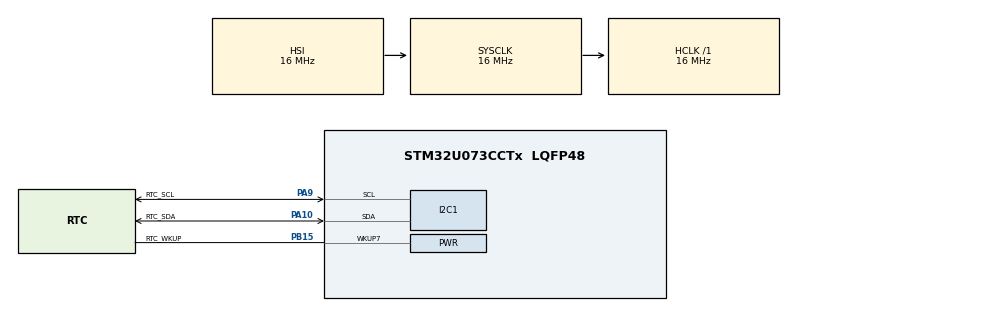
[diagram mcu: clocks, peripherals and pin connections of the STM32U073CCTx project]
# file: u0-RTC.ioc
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I2C1.Timing=0x00303D5B
Mcu.Family=STM32U0
Mcu.Name=STM32U073CCTx
Mcu.Package=LQFP48
NVIC.PriorityGroup=NVIC_PRIORITYGROUP_2
PA10.GPIO_Label=RTC_SDA
PA10.Mode=I2C
PA10.Signal=I2C1_SDA
PA13\ (SWDIO).GPIO_Label=SWDIO
PA13\ (SWDIO).Mode=Serial_Wire
PA13\ (SWDIO).Signal=DEBUG_JTMS-SWDIO
PA14\ (SWCLK).GPIO_Label=SWCLK
PA14\ (SWCLK).Mode=Serial_Wire
PA14\ (SWCLK).Signal=DEBUG_JTCK-SWCLK
PA9.GPIO_Label=RTC_SCL
PA9.Mode=I2C
PA9.Signal=I2C1_SCL
PB15.GPIO_Label=RTC_WKUP
PB15.Mode=WakeUp7
PB15.Signal=PWR_WKUP7
ProjectManager.HeapSize=0x200
ProjectManager.StackSize=0x400
ProjectManager.TargetToolchain=STM32CubeIDE
RCC.AHBFreq_Value=16000000
RCC.CortexFreq_Value=16000000
RCC.HCLKFreq_Value=16000000
RCC.HSE_VALUE=4000000
RCC.HSI48_VALUE=48000000
RCC.HSI_VALUE=16000000
RCC.LSE_VALUE=32768
RCC.MSI_VALUE=4000000
RCC.SYSCLKFreq_VALUE=16000000
RCC.VCOOutputFreq_Value=64000000
VP_PWR_VS_SECSignals.Mode=Security/Privilege
VP_RTC_VS_RTC_Activate.Mode=RTC_Enabled
board=custom

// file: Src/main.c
/* USER CODE BEGIN Header */
/**
  ******************************************************************************
  * @file           : main.c
  * @brief          : Main program body
  ******************************************************************************
  * @attention
  *
  * Copyright (c) 2026 STMicroelectronics.
  * All rights reserved.
  *
  * This software is licensed under terms that can be found in the LICENSE file
  * in the root directory of this software component.
  * If no LICENSE file comes with this software, it is provided AS-IS.
  *
  ******************************************************************************
  */
/* USER CODE END Header */
#include "main.h"

/* USER CODE BEGIN Includes */
#include "RV3028.h"
/* USER CODE END Includes */

I2C_HandleTypeDef hi2c1;

RTC_HandleTypeDef hrtc;

void SystemClock_Config(void);
static void MX_GPIO_Init(void);
static void MX_I2C1_Init(void);
static void MX_RTC_Init(void);

int main(void)
{

  /* MCU Configuration--------------------------------------------------------*/

  /* Reset of all peripherals, Initializes the Flash interface and the Systick. */
  HAL_Init();

  /* Configure the system clock */
  SystemClock_Config();

  /* Initialize all configured peripherals */
  MX_GPIO_Init();
  MX_I2C1_Init();
  MX_RTC_Init();
  /* USER CODE BEGIN 2 */
  //be able to debug in shutdown mode
  HAL_DBGMCU_EnableDBGStandbyMode();

  //wait until EEbusy low (not busy)
  uint8_t buffer[1];
  do{
	  RTC_read_register_value(&hi2c1, 0x0E, buffer, 1);
	  HAL_Delay(10);
  } while(buffer[0] & 0b10000000);

  HAL_StatusTypeDef status;

  if(__HAL_RCC_GET_FLAG(RCC_FLAG_PWRRST) == SET){
	  HAL_Delay(10000);
	  do{ status = RTC_init(&hi2c1); HAL_Delay(10); } while(status != HAL_OK);
	  __HAL_RCC_CLEAR_RESET_FLAGS(); //clear so it doesn't trigger on next cycle
  }

  //set time to 10 seconds before interrupt
  uint8_t time[] = {0x50,0x00,0x00,0x00,0b00000001,0b00000001,0x00};
  do{ status = RTC_set_register_value(&hi2c1, 0x00, time, 7); HAL_Delay(10); } while(status != HAL_OK);

  RTC_handle_interrupt(&hi2c1);

  HAL_Delay(3000); //DO NOT REMOVE, delay so debugger has time to connect and flash

  //increment day count (and store it) if woken from RTC/wakeup pin 7
  if(__HAL_PWR_GET_FLAG(PWR_FLAG_WUF7) == SET){
	  HAL_PWR_EnableBkUpAccess();
	  uint32_t dayCount = HAL_RTCEx_BKUPRead(&hrtc, RTC_BKP_DR0); //init value = 0
	  dayCount++;
	  HAL_RTCEx_BKUPWrite(&hrtc, RTC_BKP_DR0, dayCount);
	  HAL_PWR_DisableBkUpAccess();
  }

  //clears the wakeup flags from all pins by writing to power reset register which will clear power status register
  __HAL_PWR_CLEAR_FLAG(PWR_FLAG_WU);

  //Sets SLEEPDEEP bit, LPMS = 1xx in PWR_CR1 register, wakeup on interrupt (WFI)
  HAL_PWR_EnterSHUTDOWNMode();

  /* USER CODE END 2 */

  /* Infinite loop */
  while (1){

  }
}

void SystemClock_Config(void)
{
  RCC_OscInitTypeDef RCC_OscInitStruct = {0};
  RCC_ClkInitTypeDef RCC_ClkInitStruct = {0};

  /** Configure the main internal regulator output voltage
  */
  HAL_PWREx_ControlVoltageScaling(PWR_REGULATOR_VOLTAGE_SCALE2);

  /** Initializes the RCC Oscillators according to the specified parameters
  * in the RCC_OscInitTypeDef structure.
  */
  RCC_OscInitStruct.OscillatorType = RCC_OSCILLATORTYPE_HSI|RCC_OSCILLATORTYPE_LSI;
  RCC_OscInitStruct.HSIState = RCC_HSI_ON;
  RCC_OscInitStruct.HSICalibrationValue = RCC_HSICALIBRATION_DEFAULT;
  RCC_OscInitStruct.LSIState = RCC_LSI_ON;
  RCC_OscInitStruct.PLL.PLLState = RCC_PLL_NONE;
  if (HAL_RCC_OscConfig(&RCC_OscInitStruct) != HAL_OK)
  {
    Error_Handler();
  }

  /** Initializes the CPU, AHB and APB buses clocks
  */
  RCC_ClkInitStruct.ClockType = RCC_CLOCKTYPE_HCLK|RCC_CLOCKTYPE_SYSCLK
                              |RCC_CLOCKTYPE_PCLK1;
  RCC_ClkInitStruct.SYSCLKSource = RCC_SYSCLKSOURCE_HSI;
  RCC_ClkInitStruct.AHBCLKDivider = RCC_SYSCLK_DIV1;
  RCC_ClkInitStruct.APB1CLKDivider = RCC_HCLK_DIV1;

  if (HAL_RCC_ClockConfig(&RCC_ClkInitStruct, FLASH_LATENCY_1) != HAL_OK)
  {
    Error_Handler();
  }
}

static void MX_I2C1_Init(void)
{

  hi2c1.Instance = I2C1;
  hi2c1.Init.Timing = 0x00303D5B;
  hi2c1.Init.OwnAddress1 = 0;
  hi2c1.Init.AddressingMode = I2C_ADDRESSINGMODE_7BIT;
  hi2c1.Init.DualAddressMode = I2C_DUALADDRESS_DISABLE;
  hi2c1.Init.OwnAddress2 = 0;
  hi2c1.Init.OwnAddress2Masks = I2C_OA2_NOMASK;
  hi2c1.Init.GeneralCallMode = I2C_GENERALCALL_DISABLE;
  hi2c1.Init.NoStretchMode = I2C_NOSTRETCH_DISABLE;
  if (HAL_I2C_Init(&hi2c1) != HAL_OK)
  {
    Error_Handler();
  }

  /** Configure Analogue filter
  */
  if (HAL_I2CEx_ConfigAnalogFilter(&hi2c1, I2C_ANALOGFILTER_ENABLE) != HAL_OK)
  {
    Error_Handler();
  }

  /** Configure Digital filter
  */
  if (HAL_I2CEx_ConfigDigitalFilter(&hi2c1, 0) != HAL_OK)
  {
    Error_Handler();
  }

}

static void MX_RTC_Init(void)
{

  /** Initialize RTC Only
  */
  hrtc.Instance = RTC;
  hrtc.Init.HourFormat = RTC_HOURFORMAT_24;
  hrtc.Init.AsynchPrediv = 127;
  hrtc.Init.SynchPrediv = 255;
  hrtc.Init.OutPut = RTC_OUTPUT_DISABLE;
  hrtc.Init.OutPutRemap = RTC_OUTPUT_REMAP_NONE;
  hrtc.Init.OutPutPolarity = RTC_OUTPUT_POLARITY_HIGH;
  hrtc.Init.OutPutType = RTC_OUTPUT_TYPE_OPENDRAIN;
  hrtc.Init.OutPutPullUp = RTC_OUTPUT_PULLUP_NONE;
  hrtc.Init.BinMode = RTC_BINARY_NONE;
  if (HAL_RTC_Init(&hrtc) != HAL_OK)
  {
    Error_Handler();
  }

}

static void MX_GPIO_Init(void)
{
  GPIO_InitTypeDef GPIO_InitStruct = {0};

  /* GPIO Ports Clock Enable */
  __HAL_RCC_GPIOC_CLK_ENABLE();
  __HAL_RCC_GPIOF_CLK_ENABLE();
  __HAL_RCC_GPIOA_CLK_ENABLE();
  __HAL_RCC_GPIOB_CLK_ENABLE();

  /*Configure GPIO pins : PC13 PC14 PC15 */
  GPIO_InitStruct.Pin = GPIO_PIN_13|GPIO_PIN_14|GPIO_PIN_15;
  GPIO_InitStruct.Mode = GPIO_MODE_ANALOG;
  GPIO_InitStruct.Pull = GPIO_NOPULL;
  HAL_GPIO_Init(GPIOC, &GPIO_InitStruct);

  /*Configure GPIO pins : PF0 PF1 PF2 PF3 */
  GPIO_InitStruct.Pin = GPIO_PIN_0|GPIO_PIN_1|GPIO_PIN_2|GPIO_PIN_3;
  GPIO_InitStruct.Mode = GPIO_MODE_ANALOG;
  GPIO_InitStruct.Pull = GPIO_NOPULL;
  HAL_GPIO_Init(GPIOF, &GPIO_InitStruct);

  /*Configure GPIO pins : PA0 PA1 PA2 PA3
                           PA4 PA5 PA6 PA7
                           PA8 PA11 PA12 PA15 */
  GPIO_InitStruct.Pin = GPIO_PIN_0|GPIO_PIN_1|GPIO_PIN_2|GPIO_PIN_3
                          |GPIO_PIN_4|GPIO_PIN_5|GPIO_PIN_6|GPIO_PIN_7
                          |GPIO_PIN_8|GPIO_PIN_11|GPIO_PIN_12|GPIO_PIN_15;
  GPIO_InitStruct.Mode = GPIO_MODE_ANALOG;
  GPIO_InitStruct.Pull = GPIO_NOPULL;
  HAL_GPIO_Init(GPIOA, &GPIO_InitStruct);

  /*Configure GPIO pins : PB0 PB1 PB2 PB10
                           PB11 PB12 PB13 PB14
                           PB3 PB4 PB5 PB6
                           PB7 PB8 PB9 */
  GPIO_InitStruct.Pin = GPIO_PIN_0|GPIO_PIN_1|GPIO_PIN_2|GPIO_PIN_10
                          |GPIO_PIN_11|GPIO_PIN_12|GPIO_PIN_13|GPIO_PIN_14
                          |GPIO_PIN_3|GPIO_PIN_4|GPIO_PIN_5|GPIO_PIN_6
                          |GPIO_PIN_7|GPIO_PIN_8|GPIO_PIN_9;
  GPIO_InitStruct.Mode = GPIO_MODE_ANALOG;
  GPIO_InitStruct.Pull = GPIO_NOPULL;
  HAL_GPIO_Init(GPIOB, &GPIO_InitStruct);

}

void Error_Handler(void)
{
  __disable_irq();
  while (1)
  {
  }
}
